# MIMXRT685S_cm33 register map
Vendor: nxp.com; File version: 1.0
CPU: CM33 r2p0, little endian, MPU, FPU, VTOR, 3 interrupt priority bits
Registers are 32-bit, read-write, reset 0x0 unless marked. A register's access mark holds for its fields unless they carry their own. Offsets are from the block's base; [hi:lo] are bit positions; {n}, {i} and the like mark numbered series.

## USDHC0 — uSDHC
Base 0x40136000
Same registers: USDHC1 0x40137000
0x00 DS_ADDR — DMA System Address
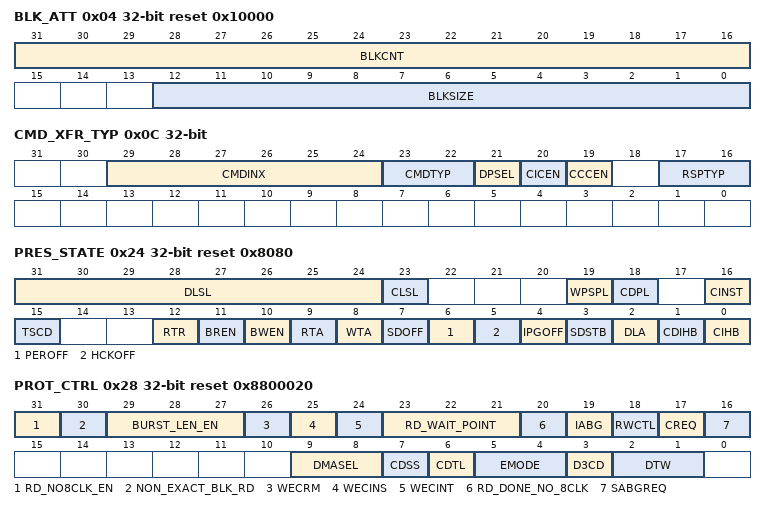
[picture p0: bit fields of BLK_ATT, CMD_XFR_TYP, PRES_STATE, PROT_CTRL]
0x04 BLK_ATT reset 0x10000 — Block Attributes
  [31:16] BLKCNT — Block Count
    0=Stop Count; 1=1 block; 2=2 blocks; 0xFFFF=65535 blocks
  [12:0] BLKSIZE — Block Size
    0=No data transfer; 1=1 Byte; 2=2 Bytes; 3=3 Bytes; 4=4 Bytes; 0x1FF=511 Bytes; 0x200=512 Bytes; 0x800=2048 Bytes; 0x1000=4096 Bytes
0x08 CMD_ARG — Command Argument
  [31:0] CMDARG
0x0C CMD_XFR_TYP — Command Transfer Type
  [29:24] CMDINX — Command Index
  [23:22] CMDTYP — Command Type
    0=Normal Other commands; 1=Suspend CMD52 for writing Bus Suspend in CCCR; 2=Resume CMD52 for writing Function Select in CCCR; 3=Abort CMD12, CMD52 for writing I/O Abort in CCCR
  [21] DPSEL — Data Present Select
    0=No Data Present; 1=Data Present
  [20] CICEN — Command Index Check Enable
    0=Disable; 1=Enable
  [19] CCCEN — Command CRC Check Enable
    0=Disable; 1=Enable
  [17:16] RSPTYP — Response Type Select
    0=No Response; 1=Response Length 136; 2=Response Length 48; 3=Response Length 48, check Busy after response
{0x10+4i} CMD_RSP{i} ro (i=0..3) — Command Response{i}
  [31:0] CMDRSP{i} — Command Response {i}
0x20 DATA_BUFF_ACC_PORT — Data Buffer Access Port
  [31:0] DATCONT — Data Content
0x24 PRES_STATE ro reset 0x8080 — Present State
  [31:24] DLSL — DATA[7:0] Line Signal Level
    {v}=DATA{v} (Data {v} line signal level) (v=0..7)
  [23] CLSL — CMD Line Signal Level
  [19] WPSPL — Write Protect Switch Pin Level
    0=Write protected (WP = 1); 1=Write enabled (WP = 0)
  [18] CDPL — Card Detect Pin Level
    0=No card present (CD_B = 1); 1=Card present (CD_B = 0)
  [16] CINST — Card Inserted
    0=Power on Reset or No Card; 1=Card Inserted
  [15] TSCD — Tape Select Change Done
    0=Delay cell select change is not finished; 1=Delay cell select change is finished
  [12] RTR — Re-Tuning Request (only for SD3.0 SDR104 mode and EMMC HS200 mode)
    0=Fixed or well tuned sampling clock; 1=Sampling clock needs re-tuning
  [11] BREN — Buffer Read Enable
    0=Read disable; 1=Read enable
  [10] BWEN — Buffer Write Enable
    0=Write disable; 1=Write enable
  [9] RTA — Read Transfer Active
    0=No valid data; 1=Transferring data
  [8] WTA — Write Transfer Active
    0=No valid data; 1=Transferring data
  [7] SDOFF — SD Clock Gated Off Internally
    0=SD Clock is active; 1=SD Clock is gated off
  [6] PEROFF — IPG_PERCLK Gated Off Internally
    0=IPG_PERCLK is active; 1=IPG_PERCLK is gated off
  [5] HCKOFF — HCLK Gated Off Internally
    0=HCLK is active; 1=HCLK is gated off
  [4] IPGOFF — IPG_CLK Gated Off Internally
    0=IPG_CLK is active; 1=IPG_CLK is gated off
  [3] SDSTB — SD Clock Stable
    0=Clock is changing frequency and not stable; 1=Clock is stable
  [2] DLA — Data Line Active
    0=DATA Line Inactive; 1=DATA Line Active
  [1] CDIHB — Command Inhibit (DATA)
    0=Can issue command which uses the DATA line; 1=Cannot issue command which uses the DATA line
  [0] CIHB — Command Inhibit (CMD)
    0=Can issue command using only CMD line; 1=Cannot issue command
0x28 PROT_CTRL reset 0x8800020 — Protocol Control
  [31] RD_NO8CLK_EN
    0=Disable S/W RD_DONE_NO_8CLK, uSHDC determines if 8 clocks are needed automatically; 1=S/W RD_DONE_NO_8CLK is enabled
  [30] NON_EXACT_BLK_RD
    0=The block read is exact block read. Host driver doesn't need to issue abort command to terminate this multi-block read.; 1=The block read is non-exact block read. Host driver needs to issue abort command to terminate this multi-block read.
  [29:27] BURST_LEN_EN — BURST length enable for INCR, INCR4 / INCR8 / INCR16, INCR4-WRAP / INCR8-WRAP / INCR16-WRAP
    0bxx1=Burst length is enabled for INCR
  [26] WECRM — Wakeup Event Enable On SD Card Removal
    0=Disable; 1=Enable
  [25] WECINS — Wakeup Event Enable On SD Card Insertion
    0=Disable; 1=Enable
  [24] WECINT — Wakeup Event Enable On Card Interrupt
    0=Disable; 1=Enable
  [23:21] RD_WAIT_POINT — Read wait point
  [20] RD_DONE_NO_8CLK
  [19] IABG — Interrupt At Block Gap
    0=Disabled; 1=Enabled
  [18] RWCTL — Read Wait Control
    0=Disable Read Wait Control, and stop SD Clock at block gap when SABGREQ bit is set; 1=Enable Read Wait Control, and assert Read Wait without stopping SD Clock at block gap when SABGREQ bit is set
  [17] CREQ — Continue Request
    0=No effect; 1=Restart
  [16] SABGREQ — Stop At Block Gap Request
    0=Transfer; 1=Stop
  [9:8] DMASEL — DMA Select
    0=No DMA or Simple DMA is selected; 1=ADMA1 is selected; 2=ADMA2 is selected
  [7] CDSS — Card Detect Signal Selection
    0=Card Detection Level is selected (for normal purpose); 1=Card Detection Test Level is selected (for test purpose)
  [6] CDTL — Card Detect Test Level
    0=Card Detect Test Level is 0, no card inserted; 1=Card Detect Test Level is 1, card inserted
  [5:4] EMODE — Endian Mode
    0=Big Endian Mode; 1=Half Word Big Endian Mode; 2=Little Endian Mode
  [3] D3CD — DATA3 as Card Detection Pin
    0=DATA3 does not monitor Card Insertion; 1=DATA3 as Card Detection Pin
  [2:1] DTW — Data Transfer Width
    0=1-bit mode; 1=4-bit mode; 2=8-bit mode
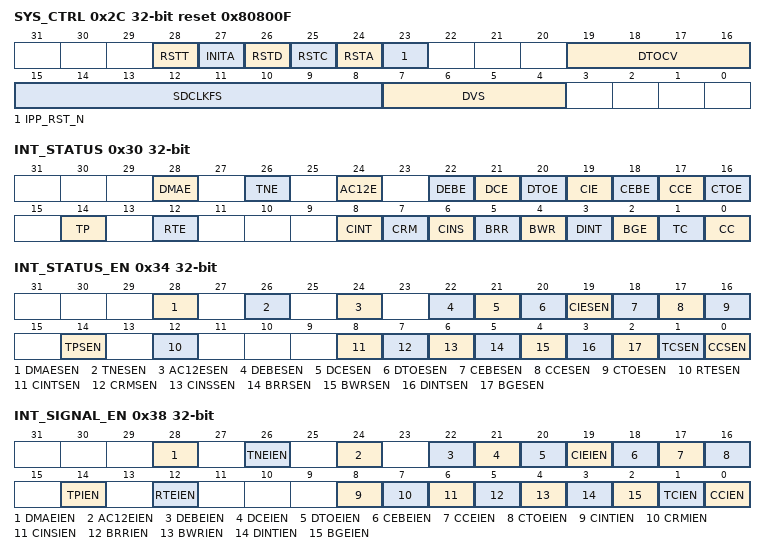
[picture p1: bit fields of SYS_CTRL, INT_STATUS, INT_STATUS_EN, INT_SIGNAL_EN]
0x2C SYS_CTRL reset 0x80800F — System Control
  [28] RSTT — Reset Tuning
  [27] INITA — Initialization Active
  [26] RSTD — Software Reset For DATA Line
    0=No Reset; 1=Reset
  [25] RSTC — Software Reset For CMD Line
    0=No Reset; 1=Reset
  [24] RSTA — Software Reset For ALL
    0=No Reset; 1=Reset
  [23] IPP_RST_N
  [19:16] DTOCV — Data Timeout Counter Value
    0=SDCLK x 2 14; 1=SDCLK x 2 15; 13=SDCLK x 2 27; 14=SDCLK x 2 28; 15=SDCLK x 2 29
  [15:8] SDCLKFS — SDCLK Frequency Select
  [7:4] DVS — Divisor
    0=Divide-by-1; 1=Divide-by-2; 14=Divide-by-15; 15=Divide-by-16
0x30 INT_STATUS write-1-clears — Interrupt Status
  [28] DMAE write-1-clears — DMA Error
    0=No Error; 1=Error
  [26] TNE write-1-clears — Tuning Error: (only for SD3.0 SDR104 mode and EMMC HS200 mode)
  [24] AC12E write-1-clears — Auto CMD12 Error
    0=No Error; 1=Error
  [22] DEBE write-1-clears — Data End Bit Error
    0=No Error; 1=Error
  [21] DCE write-1-clears — Data CRC Error
    0=No Error; 1=Error
  [20] DTOE write-1-clears — Data Timeout Error
    0=No Error; 1=Time out
  [19] CIE write-1-clears — Command Index Error
    0=No Error; 1=Error
  [18] CEBE write-1-clears — Command End Bit Error
    0=No Error; 1=End Bit Error Generated
  [17] CCE write-1-clears — Command CRC Error
    0=No Error; 1=CRC Error Generated
  [16] CTOE write-1-clears — Command Timeout Error
    0=No Error; 1=Time out
  [14] TP write-1-clears — Tuning Pass:(only for SD3.0 SDR104 mode and EMMC HS200 mode)
  [12] RTE write-1-clears — Re-Tuning Event: (only for SD3.0 SDR104 mode and EMMC HS200 mode)
    0=Re-Tuning is not required; 1=Re-Tuning should be performed
  [8] CINT write-1-clears — Card Interrupt
    0=No Card Interrupt; 1=Generate Card Interrupt
  [7] CRM write-1-clears — Card Removal
    0=Card state unstable or inserted; 1=Card removed
  [6] CINS write-1-clears — Card Insertion
    0=Card state unstable or removed; 1=Card inserted
  [5] BRR write-1-clears — Buffer Read Ready
    0=Not ready to read buffer; 1=Ready to read buffer
  [4] BWR write-1-clears — Buffer Write Ready
    0=Not ready to write buffer; 1=Ready to write buffer:
  [3] DINT write-1-clears — DMA Interrupt
    0=No DMA Interrupt; 1=DMA Interrupt is generated
  [2] BGE write-1-clears — Block Gap Event
    0=No block gap event; 1=Transaction stopped at block gap
  [1] TC write-1-clears — Transfer Complete
    0=Transfer not complete; 1=Transfer complete
  [0] CC write-1-clears — Command Complete
    0=Command not complete; 1=Command complete
0x34 INT_STATUS_EN — Interrupt Status Enable
  [all] fields
    0=Masked; 1=Enabled
  [28] DMAESEN — DMA Error Status Enable
  [26] TNESEN — Tuning Error Status Enable
  [24] AC12ESEN — Auto CMD12 Error Status Enable
  [22] DEBESEN — Data End Bit Error Status Enable
  [21] DCESEN — Data CRC Error Status Enable
  [20] DTOESEN — Data Timeout Error Status Enable
  [19] CIESEN — Command Index Error Status Enable
  [18] CEBESEN — Command End Bit Error Status Enable
  [17] CCESEN — Command CRC Error Status Enable
  [16] CTOESEN — Command Timeout Error Status Enable
  [14] TPSEN — Tuning Pass Status Enable
  [12] RTESEN — Re-Tuning Event Status Enable
  [8] CINTSEN — Card Interrupt Status Enable
  [7] CRMSEN — Card Removal Status Enable
  [6] CINSSEN — Card Insertion Status Enable
  [5] BRRSEN — Buffer Read Ready Status Enable
  [4] BWRSEN — Buffer Write Ready Status Enable
  [3] DINTSEN — DMA Interrupt Status Enable
  [2] BGESEN — Block Gap Event Status Enable
  [1] TCSEN — Transfer Complete Status Enable
  [0] CCSEN — Command Complete Status Enable
0x38 INT_SIGNAL_EN — Interrupt Signal Enable
  [28] DMAEIEN — DMA Error Interrupt Enable
    0=Masked; 1=Enable
  [26] TNEIEN — Tuning Error Interrupt Enable
    0=Masked; 1=Enabled
  [24] AC12EIEN — Auto CMD12 Error Interrupt Enable
    0=Masked; 1=Enabled
  [22] DEBEIEN — Data End Bit Error Interrupt Enable
    0=Masked; 1=Enabled
  [21] DCEIEN — Data CRC Error Interrupt Enable
    0=Masked; 1=Enabled
  [20] DTOEIEN — Data Timeout Error Interrupt Enable
    0=Masked; 1=Enabled
  [19] CIEIEN — Command Index Error Interrupt Enable
    0=Masked; 1=Enabled
  [18] CEBEIEN — Command End Bit Error Interrupt Enable
    0=Masked; 1=Enabled
  [17] CCEIEN — Command CRC Error Interrupt Enable
    0=Masked; 1=Enabled
  [16] CTOEIEN — Command Timeout Error Interrupt Enable
    0=Masked; 1=Enabled
  [14] TPIEN — Tuning Pass Interrupt Enable
    0=Masked; 1=Enabled
  [12] RTEIEN — Re-Tuning Event Interrupt Enable
    0=Masked; 1=Enabled
  [8] CINTIEN — Card Interrupt Interrupt Enable
    0=Masked; 1=Enabled
  [7] CRMIEN — Card Removal Interrupt Enable
    0=Masked; 1=Enabled
  [6] CINSIEN — Card Insertion Interrupt Enable
    0=Masked; 1=Enabled
  [5] BRRIEN — Buffer Read Ready Interrupt Enable
    0=Masked; 1=Enabled
  [4] BWRIEN — Buffer Write Ready Interrupt Enable
    0=Masked; 1=Enabled
  [3] DINTIEN — DMA Interrupt Enable
    0=Masked; 1=Enabled
  [2] BGEIEN — Block Gap Event Interrupt Enable
    0=Masked; 1=Enabled
  [1] TCIEN — Transfer Complete Interrupt Enable
    0=Masked; 1=Enabled
  [0] CCIEN — Command Complete Interrupt Enable
    0=Masked; 1=Enabled
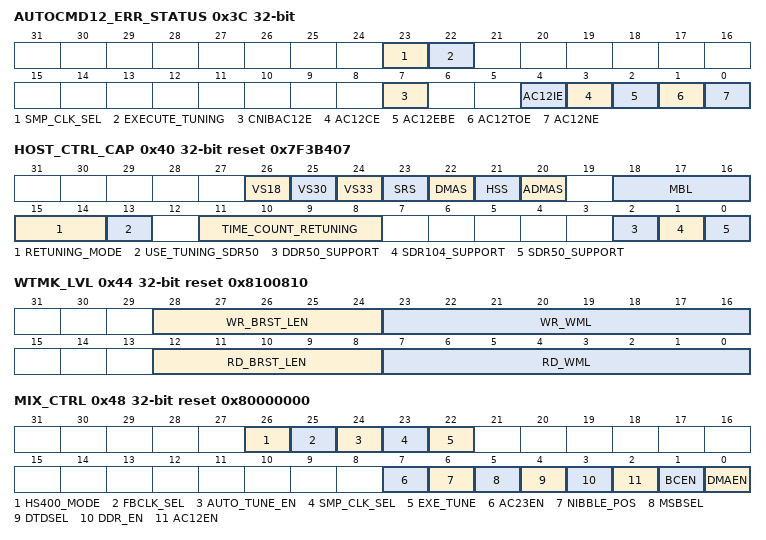
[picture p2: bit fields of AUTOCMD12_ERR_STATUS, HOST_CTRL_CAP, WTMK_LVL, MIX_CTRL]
0x3C AUTOCMD12_ERR_STATUS — Auto CMD12 Error Status
  [23] SMP_CLK_SEL — Sample Clock Select
    0=Fixed clock is used to sample data; 1=Tuned clock is used to sample data
  [22] EXECUTE_TUNING
  [7] CNIBAC12E ro — Command Not Issued By Auto CMD12 Error
    0=No error; 1=Not Issued
  [4] AC12IE ro — Auto CMD12 / 23 Index Error
    0=No error; 1=Error, the CMD index in response is not CMD12/23
  [3] AC12CE ro — Auto CMD12 / 23 CRC Error
    0=No CRC error; 1=CRC Error Met in Auto CMD12/23 Response
  [2] AC12EBE ro — Auto CMD12 / 23 End Bit Error
    0=No error; 1=End Bit Error Generated
  [1] AC12TOE ro — Auto CMD12 / 23 Timeout Error
    0=No error; 1=Time out
  [0] AC12NE ro — Auto CMD12 Not Executed
    0=Executed; 1=Not executed
0x40 HOST_CTRL_CAP reset 0x7F3B407 — Host Controller Capabilities
  [26] VS18 ro — Voltage Support 1.8 V
    0=1.8V not supported; 1=1.8V supported
  [25] VS30 ro — Voltage Support 3.0 V
    0=3.0V not supported; 1=3.0V supported
  [24] VS33 ro — Voltage Support 3.3V
    0=3.3V not supported; 1=3.3V supported
  [23] SRS ro — Suspend / Resume Support
    0=Not supported; 1=Supported
  [22] DMAS ro — DMA Support
    0=DMA not supported; 1=DMA Supported
  [21] HSS ro — High Speed Support
    0=High Speed Not Supported; 1=High Speed Supported
  [20] ADMAS ro — ADMA Support
    0=Advanced DMA Not supported; 1=Advanced DMA Supported
  [18:16] MBL ro — Max Block Length
    0=512 bytes; 1=1024 bytes; 2=2048 bytes; 3=4096 bytes
  [15:14] RETUNING_MODE ro
    0=Mode 1; 1=Mode 2; 2=Mode 3
  [13] USE_TUNING_SDR50 — Use Tuning for SDR50
    0=SDR does not require tuning; 1=SDR50 requires tuning
  [11:8] TIME_COUNT_RETUNING — Time Counter for Retuning
  [2] DDR50_SUPPORT ro
  [1] SDR104_SUPPORT ro
  [0] SDR50_SUPPORT ro
0x44 WTMK_LVL reset 0x8100810 — Watermark Level
  [28:24] WR_BRST_LEN — Write Burst Length Due to system restriction, the actual burst length may not exceed 16.
  [23:16] WR_WML — Write Watermark Level
  [12:8] RD_BRST_LEN — Read Burst Length Due to system restriction, the actual burst length may not exceed 16.
  [7:0] RD_WML — Read Watermark Level
0x48 MIX_CTRL reset 0x80000000 — Mixer Control
  [26] HS400_MODE — Enable HS400 Mode
  [25] FBCLK_SEL — Feedback Clock Source Selection (Only used for SD3.0, SDR104 mode and EMMC HS200 mode)
    0=Feedback clock comes from the loopback CLK; 1=Feedback clock comes from the ipp_card_clk_out
  [24] AUTO_TUNE_EN — Auto Tuning Enable (Only used for SD3.0, SDR104 mode and and EMMC HS200 mode)
    0=Disable auto tuning; 1=Enable auto tuning
  [23] SMP_CLK_SEL
    0=Fixed clock is used to sample data / cmd; 1=Tuned clock is used to sample data / cmd
  [22] EXE_TUNE — Execute Tuning: (Only used for SD3.0, SDR104 mode and EMMC HS200 mode)
    0=Not Tuned or Tuning Completed; 1=Execute Tuning
  [7] AC23EN — Auto CMD23 Enable
  [6] NIBBLE_POS
  [5] MSBSEL — Multi / Single Block Select
    0=Single Block; 1=Multiple Blocks
  [4] DTDSEL — Data Transfer Direction Select
    0=Write (Host to Card); 1=Read (Card to Host)
  [3] DDR_EN — Dual Data Rate mode selection
  [2] AC12EN — Auto CMD12 Enable
    0=Disable; 1=Enable
  [1] BCEN — Block Count Enable
    0=Disable; 1=Enable
  [0] DMAEN — DMA Enable
    0=Disable; 1=Enable
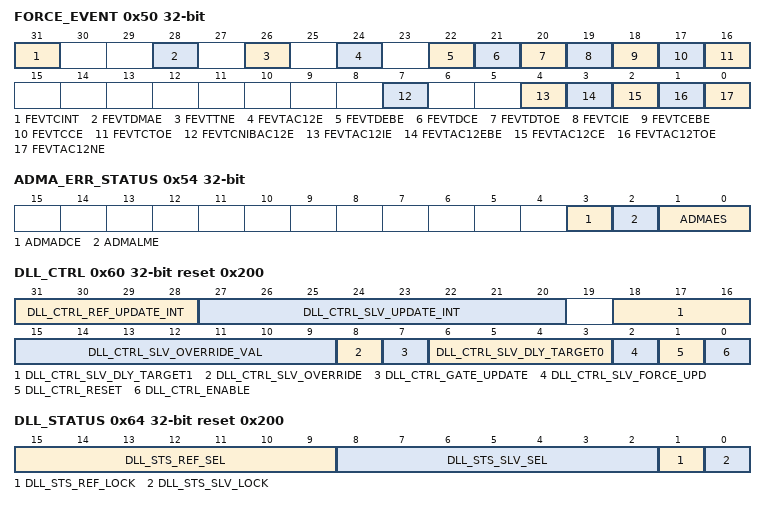
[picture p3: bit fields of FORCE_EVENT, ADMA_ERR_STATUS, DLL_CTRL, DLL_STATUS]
0x50 FORCE_EVENT
  [31] FEVTCINT — Force Event Card Interrupt
  [28] FEVTDMAE — Force Event DMA Error
  [26] FEVTTNE — Force Tuning Error
  [24] FEVTAC12E — Force Event Auto Command 12 Error
  [22] FEVTDEBE — Force Event Data End Bit Error
  [21] FEVTDCE — Force Event Data CRC Error
  [20] FEVTDTOE — Force Event Data Time Out Error
  [19] FEVTCIE — Force Event Command Index Error
  [18] FEVTCEBE — Force Event Command End Bit Error
  [17] FEVTCCE — Force Event Command CRC Error
  [16] FEVTCTOE — Force Event Command Time Out Error
  [7] FEVTCNIBAC12E — Force Event Command Not Executed By Auto Command 12 Error
  [4] FEVTAC12IE — Force Event Auto Command 12 Index Error
  [3] FEVTAC12EBE — Force Event Auto Command 12 End Bit Error
  [2] FEVTAC12CE — Force Event Auto Command 12 CRC Error
  [1] FEVTAC12TOE — Force Event Auto Command 12 Time Out Error
  [0] FEVTAC12NE — Force Event Auto Command 12 Not Executed
0x54 ADMA_ERR_STATUS ro — ADMA Error Status Register
  [3] ADMADCE — ADMA Descriptor Error
    0=No Error; 1=Error
  [2] ADMALME — ADMA Length Mismatch Error
    0=No Error; 1=Error
  [1:0] ADMAES — ADMA Error State (when ADMA Error is occurred)
0x58 ADMA_SYS_ADDR — ADMA System Address
  [31:2] ADS_ADDR
0x60 DLL_CTRL reset 0x200 — DLL (Delay Line) Control
  [31:28] DLL_CTRL_REF_UPDATE_INT, [27:20] DLL_CTRL_SLV_UPDATE_INT, [18:16] DLL_CTRL_SLV_DLY_TARGET1, [15:9] DLL_CTRL_SLV_OVERRIDE_VAL, [8] DLL_CTRL_SLV_OVERRIDE, [7] DLL_CTRL_GATE_UPDATE, [6:3] DLL_CTRL_SLV_DLY_TARGET0, [2] DLL_CTRL_SLV_FORCE_UPD, [1] DLL_CTRL_RESET, [0] DLL_CTRL_ENABLE
0x64 DLL_STATUS ro reset 0x200
  [15:9] DLL_STS_REF_SEL, [8:2] DLL_STS_SLV_SEL, [1] DLL_STS_REF_LOCK, [0] DLL_STS_SLV_LOCK
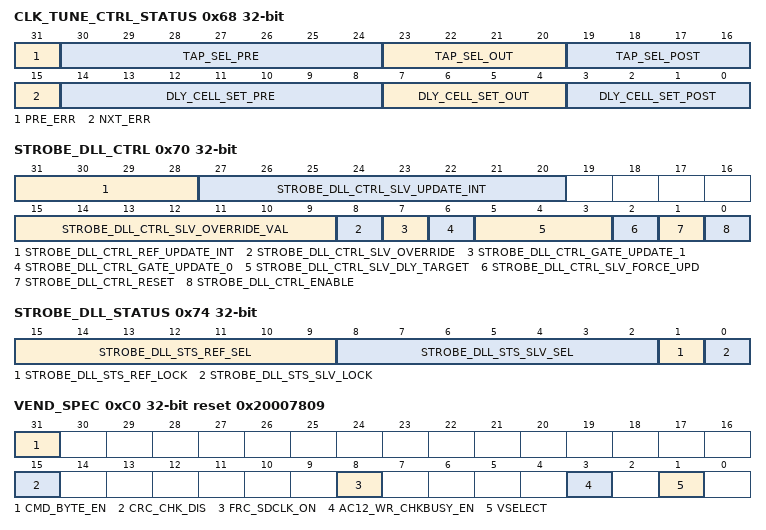
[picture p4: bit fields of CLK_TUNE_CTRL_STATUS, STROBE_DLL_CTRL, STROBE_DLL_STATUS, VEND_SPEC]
0x68 CLK_TUNE_CTRL_STATUS — CLK Tuning Control and Status
  [31] PRE_ERR ro, [30:24] TAP_SEL_PRE ro, [23:20] TAP_SEL_OUT ro, [19:16] TAP_SEL_POST ro, [15] NXT_ERR ro, [14:8] DLY_CELL_SET_PRE, [7:4] DLY_CELL_SET_OUT, [3:0] DLY_CELL_SET_POST
0x70 STROBE_DLL_CTRL — Strobe DLL Control
  [31:28] STROBE_DLL_CTRL_REF_UPDATE_INT — Strobe DLL Control Reference Update Interval
  [27:20] STROBE_DLL_CTRL_SLV_UPDATE_INT — Strobe DLL Control Slave Update Interval
  [15:9] STROBE_DLL_CTRL_SLV_OVERRIDE_VAL — Strobe DLL Control Slave Override Value
  [8] STROBE_DLL_CTRL_SLV_OVERRIDE — Strobe DLL Control Slave Override
  [7] STROBE_DLL_CTRL_GATE_UPDATE_1 — Strobe DLL Control Gate Update
  [6] STROBE_DLL_CTRL_GATE_UPDATE_0 — Strobe DLL Control Gate Update
  [5:3] STROBE_DLL_CTRL_SLV_DLY_TARGET — Strobe DLL Control Slave Delay Target
  [2] STROBE_DLL_CTRL_SLV_FORCE_UPD — Strobe DLL Control Slave Force Updated
  [1] STROBE_DLL_CTRL_RESET — Strobe DLL Control Reset
  [0] STROBE_DLL_CTRL_ENABLE — Strobe DLL Control Enable
0x74 STROBE_DLL_STATUS ro
  [15:9] STROBE_DLL_STS_REF_SEL — Strobe DLL Status Reference Select
  [8:2] STROBE_DLL_STS_SLV_SEL — Strobe DLL Status Slave Select
  [1] STROBE_DLL_STS_REF_LOCK — Strobe DLL Status Reference Lock
  [0] STROBE_DLL_STS_SLV_LOCK — Strobe DLL Status Slave Lock
0xC0 VEND_SPEC reset 0x20007809 — Vendor Specific Register
  [31] CMD_BYTE_EN — Byte access
    0=Disable; 1=Enable
  [15] CRC_CHK_DIS — CRC Check Disable
    0=Check CRC16 for every read data packet and check CRC bits for every write data packet; 1=Ignore CRC16 check for every read data packet and ignore CRC bits check for every write data packet
  [8] FRC_SDCLK_ON — Force CLK
    0=CLK active or inactive is fully controlled by the hardware; 1=Force CLK active
  [3] AC12_WR_CHKBUSY_EN — Check busy enable
    0=Do not check busy after auto CMD12 for write data packet; 1=Check busy after auto CMD12 for write data packet
  [1] VSELECT — Voltage selection
    0=Change the voltage to high voltage range, around 3.0 V; 1=Change the voltage to low voltage range, around 1.8 V
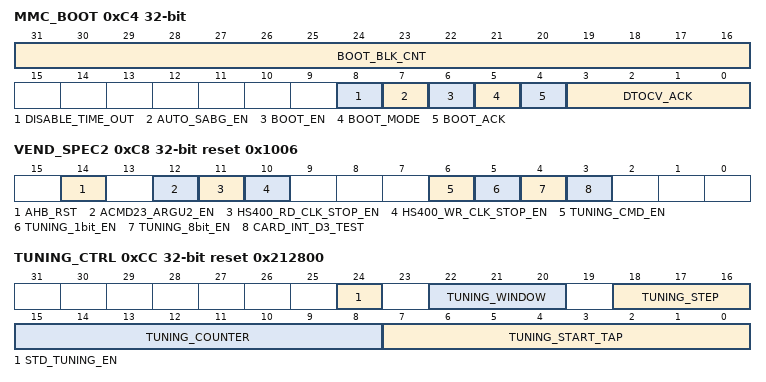
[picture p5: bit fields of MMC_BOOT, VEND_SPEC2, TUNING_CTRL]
0xC4 MMC_BOOT
  [31:16] BOOT_BLK_CNT
  [8] DISABLE_TIME_OUT
    0=Enable time out; 1=Disable time out
  [7] AUTO_SABG_EN
  [6] BOOT_EN
    0=Fast boot disable; 1=Fast boot enable
  [5] BOOT_MODE
    0=Normal boot; 1=Alternative boot
  [4] BOOT_ACK
    0=No ack; 1=Ack
  [3:0] DTOCV_ACK
    {v}=SDCLK x 2^{v+14} (v=0..7); 14=SDCLK x 2^28; 15=SDCLK x 2^29
0xC8 VEND_SPEC2 reset 0x1006 — Vendor Specific 2 Register
  [14] AHB_RST — AHB BUS reset
  [12] ACMD23_ARGU2_EN — Argument2 register enable for ACMD23
    0=Disable; 1=Argument2 register enable for ACMD23 sharing with SDMA system address register. Default is enable.
  [11] HS400_RD_CLK_STOP_EN — HS400 Read Clock Stop Enable
  [10] HS400_WR_CLK_STOP_EN — HS400 Write Clock Stop Enable
  [6] TUNING_CMD_EN
    0=Auto tuning circuit does not check the CMD line; 1=Auto tuning circuit checks the CMD line
  [5] TUNING_1bit_EN
  [4] TUNING_8bit_EN
  [3] CARD_INT_D3_TEST — Card Interrupt Detection Test
    0=Check the card interrupt only when DATA3 is high; 1=Check the card interrupt by ignoring the status of DATA3
0xCC TUNING_CTRL reset 0x212800 — Tuning Control Register
  [24] STD_TUNING_EN, [22:20] TUNING_WINDOW, [18:16] TUNING_STEP, [15:8] TUNING_COUNTER, [7:0] TUNING_START_TAP
